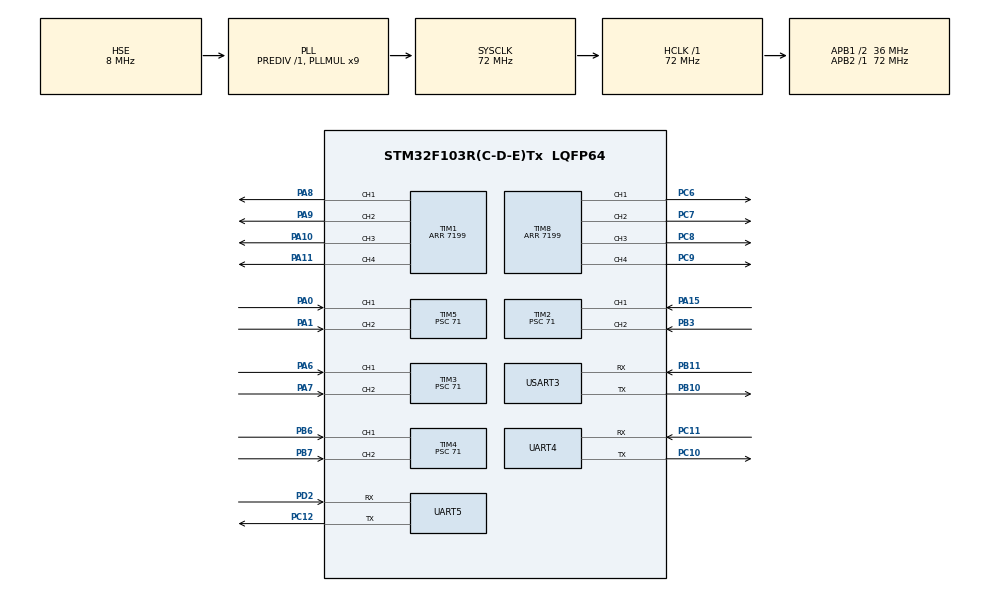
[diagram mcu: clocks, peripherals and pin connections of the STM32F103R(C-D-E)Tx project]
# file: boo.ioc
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Dma.Request0=UART4_RX
Dma.UART4_RX.0.Direction=DMA_PERIPH_TO_MEMORY
Dma.UART4_RX.0.Instance=DMA2_Channel3
Dma.UART4_RX.0.MemDataAlignment=DMA_MDATAALIGN_BYTE
Dma.UART4_RX.0.MemInc=DMA_MINC_ENABLE
Dma.UART4_RX.0.Mode=DMA_NORMAL
Dma.UART4_RX.0.PeriphDataAlignment=DMA_PDATAALIGN_BYTE
Dma.UART4_RX.0.PeriphInc=DMA_PINC_DISABLE
Dma.UART4_RX.0.Priority=DMA_PRIORITY_LOW
FREERTOS.Tasks01=defaultTask,0,128,StartDefaultTask,Default,NULL,Dynamic,NULL,NULL
Mcu.Family=STM32F1
Mcu.Name=STM32F103R(C-D-E)Tx
Mcu.Package=LQFP64
NVIC.DMA2_Channel3_IRQn=true\:5\:0\:false\:false\:true\:true\:false\:true
NVIC.PriorityGroup=NVIC_PRIORITYGROUP_4
NVIC.TIM2_IRQn=true\:5\:0\:false\:false\:true\:true\:true\:true
NVIC.TIM3_IRQn=true\:5\:0\:false\:false\:true\:true\:true\:true
NVIC.TIM4_IRQn=true\:5\:0\:false\:false\:true\:true\:true\:true
NVIC.TIM5_IRQn=true\:5\:0\:false\:false\:true\:true\:true\:true
NVIC.TIM7_IRQn=true\:15\:0\:false\:false\:true\:false\:false\:true
NVIC.TimeBase=TIM7_IRQn
NVIC.TimeBaseIP=TIM7
NVIC.UART4_IRQn=true\:5\:0\:false\:false\:true\:true\:true\:true
NVIC.UART5_IRQn=true\:5\:0\:false\:false\:true\:true\:true\:true
NVIC.USART3_IRQn=true\:5\:0\:false\:false\:true\:true\:true\:true
PA0-WKUP.GPIO_PuPd=GPIO_PULLDOWN
PA0-WKUP.Signal=S_TIM5_CH1
PA1.GPIO_PuPd=GPIO_PULLDOWN
PA1.Signal=S_TIM5_CH2
PA10.Signal=S_TIM1_CH3
PA11.Signal=S_TIM1_CH4
PA13.Mode=Serial_Wire
PA13.Signal=SYS_JTMS-SWDIO
PA14.Mode=Serial_Wire
PA14.Signal=SYS_JTCK-SWCLK
PA15.GPIO_PuPd=GPIO_PULLDOWN
PA15.Signal=S_TIM2_CH1_ETR
PA6.GPIO_PuPd=GPIO_PULLDOWN
PA6.Signal=S_TIM3_CH1
PA7.GPIO_PuPd=GPIO_PULLDOWN
PA7.Signal=S_TIM3_CH2
PA8.Signal=S_TIM1_CH1
PA9.Signal=S_TIM1_CH2
PB10.Mode=Asynchronous
PB10.Signal=USART3_TX
PB11.Mode=Asynchronous
PB11.Signal=USART3_RX
PB3.GPIO_PuPd=GPIO_PULLDOWN
PB3.Signal=S_TIM2_CH2
PB6.GPIO_PuPd=GPIO_PULLDOWN
PB6.Signal=S_TIM4_CH1
PB7.GPIO_PuPd=GPIO_PULLDOWN
PB7.Signal=S_TIM4_CH2
PC10.Mode=Asynchronous
PC10.Signal=UART4_TX
PC11.Mode=Asynchronous
PC11.Signal=UART4_RX
PC12.Mode=Asynchronous
PC12.Signal=UART5_TX
PC6.Signal=S_TIM8_CH1
PC7.Signal=S_TIM8_CH2
PC8.Signal=S_TIM8_CH3
PC9.Signal=S_TIM8_CH4
PD0-OSC_IN.Mode=HSE-External-Oscillator
PD0-OSC_IN.Signal=RCC_OSC_IN
PD1-OSC_OUT.Mode=HSE-External-Oscillator
PD1-OSC_OUT.Signal=RCC_OSC_OUT
PD2.Mode=Asynchronous
PD2.Signal=UART5_RX
ProjectManager.HeapSize=0x200
ProjectManager.StackSize=0x400
ProjectManager.TargetToolchain=MDK-ARM V5.32
RCC.AHBFreq_Value=72000000
RCC.APB1CLKDivider=RCC_HCLK_DIV2
RCC.APB1Freq_Value=36000000
RCC.APB1TimFreq_Value=72000000
RCC.APB2Freq_Value=72000000
RCC.APB2TimFreq_Value=72000000
RCC.HCLKFreq_Value=72000000
RCC.PLLMUL=RCC_PLL_MUL9
RCC.PLLSourceVirtual=RCC_PLLSOURCE_HSE
RCC.SYSCLKFreq_VALUE=72000000
RCC.SYSCLKSource=RCC_SYSCLKSOURCE_PLLCLK
RCC.USBFreq_Value=72000000
SH.S_TIM1_CH1.0=TIM1_CH1,PWM Generation1 CH1
SH.S_TIM1_CH2.0=TIM1_CH2,PWM Generation2 CH2
SH.S_TIM1_CH3.0=TIM1_CH3,PWM Generation3 CH3
SH.S_TIM1_CH4.0=TIM1_CH4,PWM Generation4 CH4
SH.S_TIM2_CH1_ETR.0=TIM2_CH1,Input_Capture1_from_TI1
SH.S_TIM2_CH2.0=TIM2_CH2,Input_Capture2_from_TI2
SH.S_TIM3_CH1.0=TIM3_CH1,Input_Capture1_from_TI1
SH.S_TIM3_CH2.0=TIM3_CH2,Input_Capture2_from_TI2
SH.S_TIM4_CH1.0=TIM4_CH1,Input_Capture1_from_TI1
SH.S_TIM4_CH2.0=TIM4_CH2,Input_Capture2_from_TI2
SH.S_TIM5_CH1.0=TIM5_CH1,Input_Capture1_from_TI1
SH.S_TIM5_CH2.0=TIM5_CH2,Input_Capture2_from_TI2
SH.S_TIM8_CH1.0=TIM8_CH1,PWM Generation1 CH1
SH.S_TIM8_CH2.0=TIM8_CH2,PWM Generation2 CH2
SH.S_TIM8_CH3.0=TIM8_CH3,PWM Generation3 CH3
SH.S_TIM8_CH4.0=TIM8_CH4,PWM Generation4 CH4
TIM1.AutoReloadPreload=TIM_AUTORELOAD_PRELOAD_ENABLE
TIM1.Channel-PWM\ Generation1\ CH1=TIM_CHANNEL_1
TIM1.Channel-PWM\ Generation2\ CH2=TIM_CHANNEL_2
TIM1.Channel-PWM\ Generation3\ CH3=TIM_CHANNEL_3
TIM1.Channel-PWM\ Generation4\ CH4=TIM_CHANNEL_4
TIM1.Period=7199
TIM2.AutoReloadPreload=TIM_AUTORELOAD_PRELOAD_ENABLE
TIM2.Channel-Input_Capture1_from_TI1=TIM_CHANNEL_1
TIM2.Channel-Input_Capture2_from_TI2=TIM_CHANNEL_2
TIM2.Prescaler=71
TIM3.AutoReloadPreload=TIM_AUTORELOAD_PRELOAD_ENABLE
TIM3.Channel-Input_Capture1_from_TI1=TIM_CHANNEL_1
TIM3.Channel-Input_Capture2_from_TI2=TIM_CHANNEL_2
TIM3.Prescaler=71
TIM4.AutoReloadPreload=TIM_AUTORELOAD_PRELOAD_ENABLE
TIM4.Channel-Input_Capture1_from_TI1=TIM_CHANNEL_1
TIM4.Channel-Input_Capture2_from_TI2=TIM_CHANNEL_2
TIM4.Prescaler=71
TIM5.AutoReloadPreload=TIM_AUTORELOAD_PRELOAD_ENABLE
TIM5.Channel-Input_Capture1_from_TI1=TIM_CHANNEL_1
TIM5.Channel-Input_Capture2_from_TI2=TIM_CHANNEL_2
TIM5.Prescaler=71
TIM8.AutoReloadPreload=TIM_AUTORELOAD_PRELOAD_ENABLE
TIM8.Channel-PWM\ Generation1\ CH1=TIM_CHANNEL_1
TIM8.Channel-PWM\ Generation2\ CH2=TIM_CHANNEL_2
TIM8.Channel-PWM\ Generation3\ CH3=TIM_CHANNEL_3
TIM8.Channel-PWM\ Generation4\ CH4=TIM_CHANNEL_4
TIM8.Period=7199
UART4.VirtualMode=Asynchronous
UART5.VirtualMode=Asynchronous
USART3.VirtualMode=VM_ASYNC
VP_FREERTOS_VS_CMSIS_V1.Mode=CMSIS_V1
VP_SYS_VS_tim7.Mode=TIM7
VP_TIM1_VS_ClockSourceINT.Mode=Internal
VP_TIM2_VS_ClockSourceINT.Mode=Internal
VP_TIM3_VS_ClockSourceINT.Mode=Internal
VP_TIM4_VS_ClockSourceINT.Mode=Internal
VP_TIM5_VS_ClockSourceINT.Mode=Internal
VP_TIM8_VS_ClockSourceINT.Mode=Internal
board=custom

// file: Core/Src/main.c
/* USER CODE BEGIN Header */
/**
  ******************************************************************************
  * @file           : main.c
  * @brief          : Main program body
  ******************************************************************************
  * @attention
  *
  * <h2><center>&copy; Copyright (c) 2022 STMicroelectronics.
  * All rights reserved.</center></h2>
  *
  * This software component is licensed by ST under Ultimate Liberty license
  * SLA0044, the "License"; You may not use this file except in compliance with
  * the License. You may obtain a copy of the License at:
  *                             www.st.com/SLA0044
  *
  ******************************************************************************
  */
/* USER CODE END Header */
#include "main.h"
#include "cmsis_os.h"
#include "dma.h"
#include "tim.h"
#include "usart.h"
#include "gpio.h"

/* USER CODE BEGIN Includes */
#include "Start_task.h"
/* USER CODE END Includes */

void SystemClock_Config(void);
void MX_FREERTOS_Init(void);

int main(void)
{

  /* MCU Configuration--------------------------------------------------------*/

  /* Reset of all peripherals, Initializes the Flash interface and the Systick. */
  HAL_Init();

  /* Configure the system clock */
  SystemClock_Config();

  /* Initialize all configured peripherals */
  MX_GPIO_Init();
  MX_TIM1_Init();
  MX_TIM2_Init();
  MX_TIM3_Init();
  MX_TIM4_Init();
  MX_TIM5_Init();
  MX_TIM8_Init();
  MX_DMA_Init();
  MX_UART4_Init();
  MX_UART5_Init();
  MX_USART3_UART_Init();
  /* USER CODE BEGIN 2 */
	Start_task_create();
  /* USER CODE END 2 */

  /* Call init function for freertos objects (in freertos.c) */
  //MX_FREERTOS_Init();
  /* Start scheduler */
  osKernelStart();

  /* We should never get here as control is now taken by the scheduler */
  /* Infinite loop */
  while (1)
  {

  }
}

void SystemClock_Config(void)
{
  RCC_OscInitTypeDef RCC_OscInitStruct = {0};
  RCC_ClkInitTypeDef RCC_ClkInitStruct = {0};

  /** Initializes the RCC Oscillators according to the specified parameters
  * in the RCC_OscInitTypeDef structure.
  */
  RCC_OscInitStruct.OscillatorType = RCC_OSCILLATORTYPE_HSE;
  RCC_OscInitStruct.HSEState = RCC_HSE_ON;
  RCC_OscInitStruct.HSEPredivValue = RCC_HSE_PREDIV_DIV1;
  RCC_OscInitStruct.HSIState = RCC_HSI_ON;
  RCC_OscInitStruct.PLL.PLLState = RCC_PLL_ON;
  RCC_OscInitStruct.PLL.PLLSource = RCC_PLLSOURCE_HSE;
  RCC_OscInitStruct.PLL.PLLMUL = RCC_PLL_MUL9;
  if (HAL_RCC_OscConfig(&RCC_OscInitStruct) != HAL_OK)
  {
    Error_Handler();
  }
  /** Initializes the CPU, AHB and APB buses clocks
  */
  RCC_ClkInitStruct.ClockType = RCC_CLOCKTYPE_HCLK|RCC_CLOCKTYPE_SYSCLK
                              |RCC_CLOCKTYPE_PCLK1|RCC_CLOCKTYPE_PCLK2;
  RCC_ClkInitStruct.SYSCLKSource = RCC_SYSCLKSOURCE_PLLCLK;
  RCC_ClkInitStruct.AHBCLKDivider = RCC_SYSCLK_DIV1;
  RCC_ClkInitStruct.APB1CLKDivider = RCC_HCLK_DIV2;
  RCC_ClkInitStruct.APB2CLKDivider = RCC_HCLK_DIV1;

  if (HAL_RCC_ClockConfig(&RCC_ClkInitStruct, FLASH_LATENCY_2) != HAL_OK)
  {
    Error_Handler();
  }
}

void HAL_TIM_PeriodElapsedCallback(TIM_HandleTypeDef *htim)
{
  if (htim->Instance == TIM7) {
    HAL_IncTick();
  }
}

void Error_Handler(void)
{
  __disable_irq();
  while (1)
  {
  }
}

/************************ (C) COPYRIGHT STMicroelectronics *****END OF FILE****/

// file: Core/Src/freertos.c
/* USER CODE BEGIN Header */
/**
  ******************************************************************************
  * File Name          : freertos.c
  * Description        : Code for freertos applications
  ******************************************************************************
  * @attention
  *
  * <h2><center>&copy; Copyright (c) 2022 STMicroelectronics.
  * All rights reserved.</center></h2>
  *
  * This software component is licensed by ST under Ultimate Liberty license
  * SLA0044, the "License"; You may not use this file except in compliance with
  * the License. You may obtain a copy of the License at:
  *                             www.st.com/SLA0044
  *
  ******************************************************************************
  */
/* USER CODE END Header */

#include "FreeRTOS.h"
#include "task.h"
#include "main.h"
#include "cmsis_os.h"

osThreadId defaultTaskHandle;

void StartDefaultTask(void const * argument);

void MX_FREERTOS_Init(void); /* (MISRA C 2004 rule 8.1) */

/* GetIdleTaskMemory prototype (linked to static allocation support) */
void vApplicationGetIdleTaskMemory( StaticTask_t **ppxIdleTaskTCBBuffer, StackType_t **ppxIdleTaskStackBuffer, uint32_t *pulIdleTaskStackSize );

/* USER CODE BEGIN GET_IDLE_TASK_MEMORY */
static StaticTask_t xIdleTaskTCBBuffer;
static StackType_t xIdleStack[configMINIMAL_STACK_SIZE];

void vApplicationGetIdleTaskMemory( StaticTask_t **ppxIdleTaskTCBBuffer, StackType_t **ppxIdleTaskStackBuffer, uint32_t *pulIdleTaskStackSize )
{
  *ppxIdleTaskTCBBuffer = &xIdleTaskTCBBuffer;
  *ppxIdleTaskStackBuffer = &xIdleStack[0];
  *pulIdleTaskStackSize = configMINIMAL_STACK_SIZE;
  /* place for user code */
}
/* USER CODE END GET_IDLE_TASK_MEMORY */

void MX_FREERTOS_Init(void) {

  /* Create the thread(s) */
  /* definition and creation of defaultTask */
  osThreadDef(defaultTask, StartDefaultTask, osPriorityNormal, 0, 128);
  defaultTaskHandle = osThreadCreate(osThread(defaultTask), NULL);

}

void StartDefaultTask(void const * argument)
{
  for(;;)
  {
    osDelay(1);
  }
}

/************************ (C) COPYRIGHT STMicroelectronics *****END OF FILE****/
